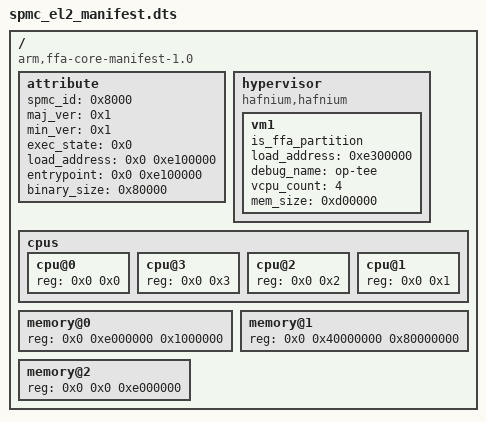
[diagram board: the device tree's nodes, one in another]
/*
 * Copyright 2022 The Hafnium Authors.
 *
 * Use of this source code is governed by a BSD-style
 * license that can be found in the LICENSE file or at
 * https://opensource.org/licenses/BSD-3-Clause.
 */

/dts-v1/;

/ {
	compatible = "arm,ffa-core-manifest-1.0";
	#address-cells = <2>;
	#size-cells = <1>;

	attribute {
		spmc_id = <0x8000>;
		maj_ver = <0x1>;
		min_ver = <0x1>;
		exec_state = <0x0>;
		load_address = <0x0 0xe100000>;
		entrypoint = <0x0 0xe100000>;
		binary_size = <0x80000>;
	};

	hypervisor {
		compatible = "hafnium,hafnium";
		vm1 {
			is_ffa_partition;
			load_address = <0xe300000>;
			debug_name = "op-tee";
			vcpu_count = <4>;
			mem_size = <0xd00000>;
		};
	};

	cpus {
		#address-cells = <0x02>;
		#size-cells = <0x00>;

		cpu@0 {
			device_type = "cpu";
			reg = <0x0 0x0>;
		};

		cpu@3 {
			device_type = "cpu";
			reg = <0x0 0x3>;
		};

		cpu@2 {
			device_type = "cpu";
			reg = <0x0 0x2>;
		};

		cpu@1 {
			device_type = "cpu";
			reg = <0x0 0x1>;
		};
	};

	/* VIRT_SECURE_MEM */
	memory@0 {
		device_type = "memory";
		reg = <0x0 0xe000000 0x1000000>;
	};

	/* NS memory */
	memory@1 {
		device_type = "ns-memory";
		reg = <0x0 0x40000000 0x80000000>;
	};

	/* Device memory */
	memory@2 {
		device_type = "device-memory";
		reg = <0x0 0x0 0xe000000>;
	};
};
